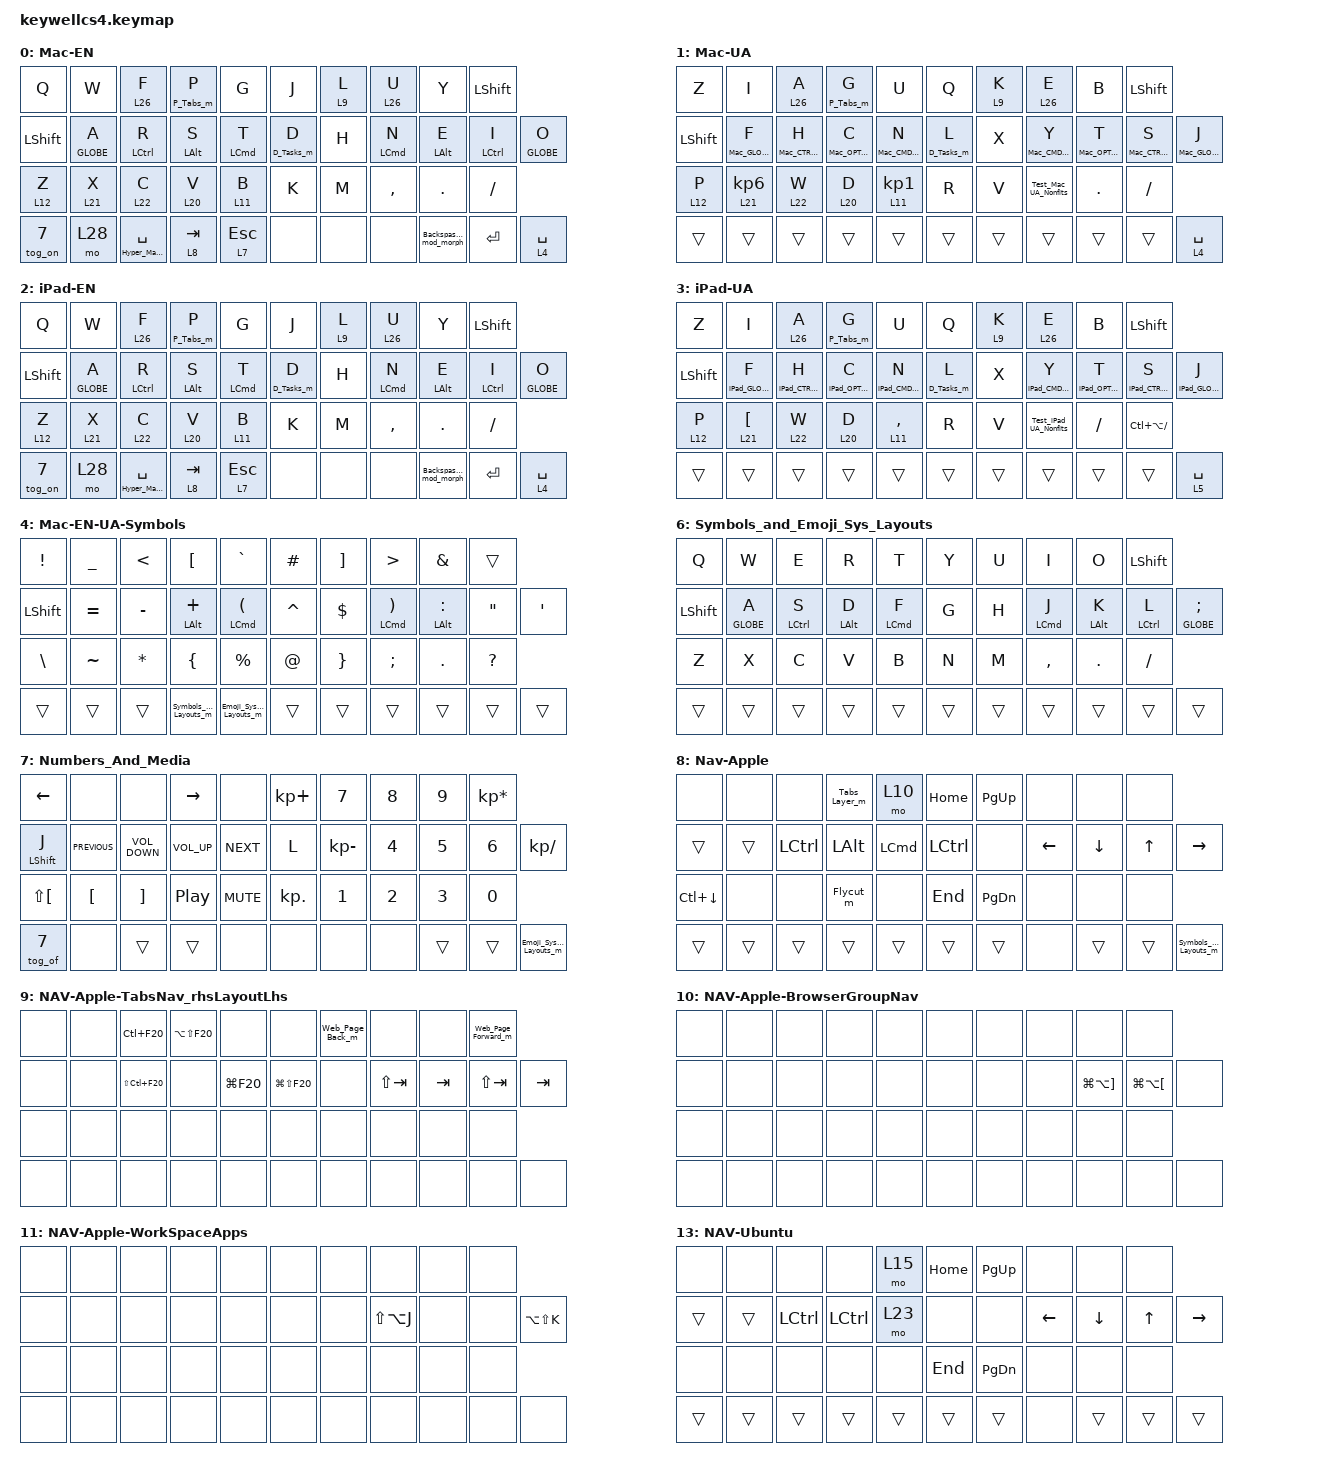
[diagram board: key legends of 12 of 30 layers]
/*
 * Copyright (c) 2020 The ZMK Contributors
 *
 * SPDX-License-Identifier: MIT
 */
// #include <dt-bindings/zmk/rgb.h>
// rob"s zmk unicode

#include <behaviors/unicode.dtsi>

/* MEH...
    Keycodes for other locales
    Gives nothing extra except key representation in visual editor
    https://github.com/nickcoutsos/keymap-editor/wiki/Keycodes-for-other-locales
*/
// #include "includes/keys_uk_enhanced.h"

#define DEFAULT 0
#define WARP  21
#define PRESISION  22

#include "includes/mouse.dtsi"
#include <zmk-unicode/keys-extra.h> // All Unicode glyphs except CJK
#include <behaviors.dtsi>
#include <dt-bindings/zmk/bt.h>
#include <dt-bindings/zmk/keys.h>
#include <dt-bindings/zmk/outputs.h>
#include <dt-bindings/zmk/pointing.h>

// rob"s zmk unicode

&uc {
    default-mode = <UC_MODE_MACOS>;
    minimum-length = <4>;
    macos-key = <LALT>;

    // linux-key = <LC(LS(U))>;
    // win-compose-key = <RALT>;
};

/ {
    behaviors {
        #include "includes/open_app_tap_dances.dtsi"

        Mac_CMD_nonEN_WA_LHRM: Mac_CMD_nonEN_WA_LHRM {
            compatible = "zmk,behavior-hold-tap";
            label = "MAC_CMD_NONEN_WA_LHRM";
            bindings = <&Mac_CMD_Shortcuts_NonEN_WA_m>, <&kp>;

            #binding-cells = <2>;
            flavor = "balanced";
            tapping-term-ms = <180>;
            quick-tap-ms = <175>;
            require-prior-idle-ms = <150>;
            hold-trigger-on-release;
            hold-trigger-key-positions = <5 6 7 8 15 16 17 18 25 26 27 28 36 37 38 39 40 41 30 31 32 33 34 35 9 19 29>;
        };

        Mac_CMD_nonEN_WA_RHRM: Mac_CMD_nonEN_WA_RHRM {
            compatible = "zmk,behavior-hold-tap";
            label = "MAC_CMD_NONEN_WA_RHRM";
            bindings = <&Mac_CMD_Shortcuts_NonEN_WA_m>, <&kp>;

            #binding-cells = <2>;
            flavor = "balanced";
            tapping-term-ms = <180>;
            quick-tap-ms = <175>;
            require-prior-idle-ms = <150>;
            hold-trigger-on-release;
            hold-trigger-key-positions = <0 1 2 3 4 10 11 12 13 14 21 22 23 24 31 32 33 34 35 36 37 38 39 40 41 30 25 15 20>;
        };

        Mac_OPT_nonEN_WA_LHRM: Mac_OPT_nonEN_WA_LHRM {
            compatible = "zmk,behavior-hold-tap";
            label = "MAC_OPT_NONEN_WA_LHRM";
            bindings = <&Mac_OPT_Shortcuts_NonEN_WA_m>, <&kp>;

            #binding-cells = <2>;
            flavor = "balanced";
            tapping-term-ms = <180>;
            quick-tap-ms = <175>;
            require-prior-idle-ms = <150>;
            hold-trigger-on-release;
            hold-trigger-key-positions = <5 6 7 8 15 16 17 18 25 26 27 28 36 37 38 39 40 41 30 31 32 33 34 35 9 19 29>;
        };

        Mac_OPT_nonEN_WA_RHRM: Mac_OPT_nonEN_WA_RHRM {
            compatible = "zmk,behavior-hold-tap";
            label = "MAC_OPT_NONEN_WA_RHRM";
            bindings = <&Mac_OPT_Shortcuts_NonEN_WA_m>, <&kp>;

            #binding-cells = <2>;
            flavor = "balanced";
            tapping-term-ms = <180>;
            quick-tap-ms = <175>;
            require-prior-idle-ms = <150>;
            hold-trigger-on-release;
            hold-trigger-key-positions = <0 1 2 3 4 10 11 12 13 14 21 22 23 24 31 32 33 34 35 36 37 38 39 40 41 30 25 15 20>;
        };

        Mac_CTRL_nonEN_WA_LHRM: Mac_CTRL_nonEN_WA_LHRM {
            compatible = "zmk,behavior-hold-tap";
            label = "MAC_CTRL_NONEN_WA_LHRM";
            #binding-cells = <2>;
            flavor = "balanced";
            tapping-term-ms = <180>;
            quick-tap-ms = <175>;
            require-prior-idle-ms = <150>;
            hold-trigger-on-release;
            hold-trigger-key-positions = <5 6 7 8 15 16 17 18 25 26 27 28 36 37 38 39 40 41 30 31 32 33 34 35 9 19 29>;
            bindings = <&Mac_CTRL_Shortcuts_NonEN_WA_m>, <&kp>;
        };

        Mac_CTRL_nonEN_WA_RHRM: Mac_CTRL_nonEN_WA_RHRM {
            compatible = "zmk,behavior-hold-tap";
            label = "MAC_CTRL_NONEN_WA_RHRM";
            #binding-cells = <2>;
            flavor = "balanced";
            tapping-term-ms = <180>;
            quick-tap-ms = <175>;
            require-prior-idle-ms = <150>;
            hold-trigger-on-release;
            bindings = <&Mac_CTRL_Shortcuts_NonEN_WA_m>, <&kp>;

            hold-trigger-key-positions = <0 1 2 3 4 10 11 12 13 14 20 21 22 23 24 30 31 32 33 34 35 36 37 38 39 40 41>;
        };

        Mac_GLOBE_nonEN_WA_LHRM: Mac_GLOBE_nonEN_WA_LHRM {
            compatible = "zmk,behavior-hold-tap";
            label = "MAC_GLOBE_NONEN_WA_LHRM";
            #binding-cells = <2>;
            flavor = "balanced";
            tapping-term-ms = <180>;
            quick-tap-ms = <175>;
            require-prior-idle-ms = <150>;
            hold-trigger-on-release;
            hold-trigger-key-positions = <5 6 7 8 15 16 17 18 25 26 27 28 36 37 38 39 40 41 30 31 32 33 34 35 9 19 29>;
            bindings = <&Mac_GLOBE_Shortcuts_NonEN_WA_m>, <&kp>;
        };

        Mac_GLOBE_nonEN_WA_RHRM: Mac_GLOBE_nonEN_WA_RHRM {
            compatible = "zmk,behavior-hold-tap";
            label = "MAC_GLOBE_NONEN_WA_RHRM";
            #binding-cells = <2>;
            flavor = "balanced";
            tapping-term-ms = <180>;
            quick-tap-ms = <175>;
            require-prior-idle-ms = <150>;
            hold-trigger-on-release;
            bindings = <&Mac_GLOBE_Shortcuts_NonEN_WA_m>, <&kp>;

            hold-trigger-key-positions = <0 1 2 3 4 10 11 12 13 14 20 21 22 23 24 30 31 32 33 34 35 36 37 38 39 40 41>;
        };

        iPad_CMD_Phonetic_UA_LHRM: iPad_CMD_Phonetic_UA_LHRM {
            compatible = "zmk,behavior-hold-tap";
            label = "IPAD_CMD_PHONETIC_UA_LHRM";
            bindings = <&iPad_CMD_Phonetic_UA_m>, <&kp>;

            #binding-cells = <2>;
            flavor = "balanced";
            tapping-term-ms = <180>;
            quick-tap-ms = <175>;
            require-prior-idle-ms = <150>;
            hold-trigger-on-release;
            hold-trigger-key-positions = <5 6 7 8 15 16 17 18 25 26 27 28 36 37 38 39 40 41 30 31 32 33 34 35 9 19 29>;
        };

        iPad_CMD_Phonetic_UA_RHRM: iPad_CMD_Phonetic_UA_RHRM {
            compatible = "zmk,behavior-hold-tap";
            label = "IPAD_CMD_PHONETIC_UA_RHRM";
            bindings = <&iPad_CMD_Phonetic_UA_m>, <&kp>;

            #binding-cells = <2>;
            flavor = "balanced";
            tapping-term-ms = <180>;
            quick-tap-ms = <175>;
            require-prior-idle-ms = <150>;
            hold-trigger-on-release;
            hold-trigger-key-positions = <0 1 2 3 4 10 11 12 13 14 21 22 23 24 31 32 33 34 35 36 37 38 39 40 41 30 25 15 20>;
        };

        iPad_OPT_Phonetic_UA_LHRM: iPad_OPT_Phonetic_UA_LHRM {
            compatible = "zmk,behavior-hold-tap";
            label = "IPAD_OPT_PHONETIC_UA_LHRM";
            bindings = <&iPad_OPT_Phonetic_UA_m>, <&kp>;

            #binding-cells = <2>;
            flavor = "balanced";
            tapping-term-ms = <180>;
            quick-tap-ms = <175>;
            require-prior-idle-ms = <150>;
            hold-trigger-on-release;
            hold-trigger-key-positions = <5 6 7 8 15 16 17 18 25 26 27 28 36 37 38 39 40 41 30 31 32 33 34 35 9 19 29>;
        };

        iPad_OPT_Phonetic_UA_RHRM: iPad_OPT_Phonetic_UA_RHRM {
            compatible = "zmk,behavior-hold-tap";
            label = "IPAD_OPT_PHONETIC_UA_RHRM";
            bindings = <&iPad_OPT_Phonetic_UA_m>, <&kp>;

            #binding-cells = <2>;
            flavor = "balanced";
            tapping-term-ms = <180>;
            quick-tap-ms = <175>;
            require-prior-idle-ms = <150>;
            hold-trigger-on-release;
            hold-trigger-key-positions = <0 1 2 3 4 10 11 12 13 14 21 22 23 24 31 32 33 34 35 36 37 38 39 40 41 30 25 15 20>;
        };

        iPad_CTRL_Phonetic_UA_LHRM: iPad_CTRL_Phonetic_UA_LHRM {
            compatible = "zmk,behavior-hold-tap";
            label = "IPAD_CTRL_PHONETIC_UA_LHRM";
            #binding-cells = <2>;
            flavor = "balanced";
            tapping-term-ms = <180>;
            quick-tap-ms = <175>;
            require-prior-idle-ms = <150>;
            hold-trigger-on-release;
            hold-trigger-key-positions = <5 6 7 8 15 16 17 18 25 26 27 28 36 37 38 39 40 41 30 31 32 33 34 35 9 19 29>;
            bindings = <&iPad_CTRL_Phonetic_UA_m>, <&kp>;
        };

        iPad_CTRL_Phonetic_UA_RHRM: iPad_CTRL_Phonetic_UA_RHRM {
            compatible = "zmk,behavior-hold-tap";
            label = "IPAD_CTRL_PHONETIC_UA_RHRM";
            #binding-cells = <2>;
            flavor = "balanced";
            tapping-term-ms = <180>;
            quick-tap-ms = <175>;
            require-prior-idle-ms = <150>;
            hold-trigger-on-release;
            bindings = <&iPad_CTRL_Phonetic_UA_m>, <&kp>;

            hold-trigger-key-positions = <0 1 2 3 4 10 11 12 13 14 20 21 22 23 24 30 31 32 33 34 35 36 37 38 39 40 41>;
        };

        iPad_GLOBE_Phonetic_UA_LHRM: iPad_GLOBE_Phonetic_UA_LHRM {
            compatible = "zmk,behavior-hold-tap";
            label = "IPAD_GLOBE_PHONETIC_UA_LHRM";
            #binding-cells = <2>;
            flavor = "balanced";
            tapping-term-ms = <180>;
            quick-tap-ms = <175>;
            require-prior-idle-ms = <150>;
            hold-trigger-on-release;
            hold-trigger-key-positions = <5 6 7 8 15 16 17 18 25 26 27 28 36 37 38 39 40 41 30 31 32 33 34 35 9 19 29>;
            bindings = <&iPad_GLOBE_Phonetic_UA_m>, <&kp>;
        };

        iPad_GLOBE_Phonetic_UA_RHRM: iPad_GLOBE_Phonetic_UA_RHRM {
            compatible = "zmk,behavior-hold-tap";
            label = "IPAD_GLOBE_PHONETIC_UA_RHRM";
            #binding-cells = <2>;
            flavor = "balanced";
            tapping-term-ms = <180>;
            quick-tap-ms = <175>;
            require-prior-idle-ms = <150>;
            hold-trigger-on-release;
            bindings = <&iPad_GLOBE_Phonetic_UA_m>, <&kp>;

            hold-trigger-key-positions = <0 1 2 3 4 10 11 12 13 14 20 21 22 23 24 30 31 32 33 34 35 36 37 38 39 40 41>;
        };

        hml: hml {
            compatible = "zmk,behavior-hold-tap";
            label = "HML";
            bindings = <&kp>, <&kp>;

            #binding-cells = <2>;
            flavor = "balanced";
            tapping-term-ms = <280>;
            quick-tap-ms = <175>;
            require-prior-idle-ms = <150>;
            hold-trigger-key-positions = <5 6 7 8 9 15 16 17 18 19 25 26 27 28 29 30 31 32 33 34 35 36 39 37 38 37 38 40 41 20>;
            hold-trigger-on-release;
        };

        hmr: hmr {
            compatible = "zmk,behavior-hold-tap";
            label = "HMR";
            bindings = <&kp>, <&kp>;

            #binding-cells = <2>;
            flavor = "balanced";
            tapping-term-ms = <280>;
            quick-tap-ms = <175>;
            require-prior-idle-ms = <150>;
            hold-trigger-on-release;
            hold-trigger-key-positions = <0 1 2 3 4 10 11 12 13 14 21 22 23 24 31 32 33 34 35 36 37 38 39 40 41 25 15>;
        };

        Layer_Tap_Timeless_Left: Layer_Tap_Timeless_Left {
            compatible = "zmk,behavior-hold-tap";
            label = "LAYER_TAP_TIMELESS_LEFT";
            bindings = <&mo>, <&kp>;

            #binding-cells = <2>;
            flavor = "balanced";
            tapping-term-ms = <280>;
            quick-tap-ms = <175>;
            require-prior-idle-ms = <150>;
            hold-trigger-on-release;
            hold-trigger-key-positions = <5 6 7 8 9 16 17 18 19 20 26 27 28 29 30 36 37 38 39 40 41 14 11 12 13>;
        };

        Backspase_MacLike_mod_morph: maclike_backspace_delete {
            compatible = "zmk,behavior-mod-morph";
            #binding-cells = <0>;
            bindings = <&kp BACKSPACE>, <&kp DELETE>;

            mods = <(MOD_LSFT)>;   // when LEFT_SHIFT is held
            keep-mods = <0>;       // don't send Shift with Delete
        };

        kt_on: key_toggle_on_only {
            compatible = "zmk,behavior-key-toggle";
            #binding-cells = <1>;
            toggle-mode = "on";   // only presses, never releases
        };

        kt_off: key_toggle_off_only {
            compatible = "zmk,behavior-key-toggle";
            #binding-cells = <1>;
            toggle-mode = "off";  // only releases, never presses
        };

        tog_on: toggle_layer_on_only {
            compatible = "zmk,behavior-toggle-layer";
            #binding-cells = <1>;
            display-name = "Toggle Layer On";
            toggle-mode = "on";
        };

        tog_of: toggle_layer_of_only {
            compatible = "zmk,behavior-toggle-layer";
            #binding-cells = <1>;
            display-name = "Toggle Layer On";
            toggle-mode = "off";
        };

        HyperMac_HT_Timeless: holdTapMacroKp {
            compatible = "zmk,behavior-hold-tap";
            label = "Hyper";
            bindings = <&Hyper_Mac_m>, <&kp>;

            #binding-cells = <2>;
            tapping-term-ms = <173>;
            hold-trigger-key-positions = <
0 1 2 3 4 5 6 7 8 9 10 11 12 13 14 15 16 17 18 19 20 21 22 23 24 25 26 27 28 29 30 31 32 33 34 35 36 37 38
             39 40 4
            >;
        };

        D_Tasks_Timeless_left: D_Tasks_Timeless_left {
            compatible = "zmk,behavior-hold-tap";
            label = "D_TASKS_TIMELESS_LEFT";
            bindings = <&D_Tasks_m>, <&kp>;

            #binding-cells = <2>;
            flavor = "balanced";
            tapping-term-ms = <280>;
            quick-tap-ms = <175>;
            require-prior-idle-ms = <150>;
            hold-trigger-key-positions = <5 6 7 8 9 16 17 18 19 26 27 28 29 30 31 32 33 34 35 36 39 37 38 37 38 40 41 20>;
            hold-trigger-on-release;
        };

        UbuntuAppSwWA_Timeless: UbuntuAppSwWA_Timeless {
            compatible = "zmk,behavior-hold-tap";
            label = "UBUNTUAPPSWWA_TIMELESS";
            bindings = <&Ubuntu_App_SW_WA_m>, <&kp>;

            #binding-cells = <2>;
            flavor = "balanced";
            tapping-term-ms = <280>;
            quick-tap-ms = <175>;
            require-prior-idle-ms = <150>;
            hold-trigger-key-positions = <5 6 7 8 9 16 17 18 19 26 27 28 29 30 31 32 33 34 35 36 39 37 38 37 38 40 41 20>;
            hold-trigger-on-release;
        };

        P_Tabs_Timeless_left: P_Tabs_Timeless_left {
            compatible = "zmk,behavior-hold-tap";
            label = "P_TABS_TIMELESS_LEFT";
            bindings = <&P_Tabs_m>, <&kp>;

            #binding-cells = <2>;
            flavor = "balanced";
            tapping-term-ms = <280>;
            quick-tap-ms = <175>;
            require-prior-idle-ms = <150>;
            hold-trigger-key-positions = <5 6 7 8 9 16 17 18 19 26 27 28 29 30 31 32 33 34 35 36 39 37 38 37 38 40 41 20>;
            hold-trigger-on-release;
        };

        Layer_Tap_Timeless_Right: Layer_Tap_Timeless_Right {
            compatible = "zmk,behavior-hold-tap";
            label = "LAYER_TAP_TIMELESS_RIGHT";
            bindings = <&mo>, <&kp>;

            #binding-cells = <2>;
            flavor = "balanced";
            tapping-term-ms = <280>;
            quick-tap-ms = <175>;
            require-prior-idle-ms = <150>;
            hold-trigger-on-release;
            hold-trigger-key-positions = <0 1 2 3 4 10 11 12 13 14 15 21 22 23 24 25 31 32 34 35 33>;
        };

        UbuntuWindowsSwWA: UbuntuWindowsSwWA {
            compatible = "zmk,behavior-hold-tap";
            label = "UBUNTUWINDOWSSWWA";
            bindings = <&Ubuntu_Windows_SW_WA_m>, <&kp>;

            #binding-cells = <2>;
            flavor = "balanced";
            tapping-term-ms = <280>;
            quick-tap-ms = <175>;
            require-prior-idle-ms = <150>;
            hold-trigger-key-positions = <5 6 7 8 9 16 17 18 19 26 27 28 29 30 31 32 33 34 35 36 39 37 38 37 38 40 41 20>;
            hold-trigger-on-release;
        };

        Thumb_HT_VeryShort: Thumb_HT_VeryShort {
            compatible = "zmk,behavior-hold-tap";
            label = "THUMB_HT_VERYSHORT";
            bindings = <&mo>, <&kp>;

            #binding-cells = <2>;
            tapping-term-ms = <120>;
            hold-trigger-key-positions = <
0 1 2 3 4 5 6 7 8 9 10 11 12 13 14 15 16 17 18 19 20 21 22 23 24 25 26 27 28 29 30 31 32 33 34 35 36 37 38
             39 40 4
            >;

            quick-tap-ms = <175>;
            flavor = "balanced";
            hold-trigger-on-release;
        };

        Sticky_1500ms: Sticky_1500ms {
            compatible = "zmk,behavior-sticky-key";
            label = "STICKY_1500MS";
            bindings = <&kp>;
            #binding-cells = <1>;
            release-after-ms = <1500>;
        };

        Thumb_HT_Normal: Thumb_HT_Normal {
            compatible = "zmk,behavior-hold-tap";
            label = "THUMB_HT_NORMAL";
            bindings = <&mo>, <&kp>;

            #binding-cells = <2>;
            tapping-term-ms = <178>;
            hold-trigger-key-positions = <
0 1 2 3 4 5 6 7 8 9 10 11 12 13 14 15 16 17 18 19 20 21 22 23 24 25 26 27 28 29 30 31 32 33 34 35 36 37 38
             39 40 4
            >;

            quick-tap-ms = <175>;
            flavor = "balanced";
            hold-trigger-on-release;
        };

        leaderKey_1: leaderKey_1 {
            compatible = "zmk,behavior-leader-key";
            #binding-cells = <0>;

            KeyCluShowShortcutsFix {
                sequence = <S H O>;
                bindings = <&KeyClu_Show_Shortcuts_m>;
            };
        };

        Test_Mac_UA_Nonfits: Test_Mac_UA_Nonfits {
            compatible = "zmk,behavior-tap-dance";
            label = "TEST_MAC_UA_NONFITS";
            #binding-cells = <0>;
            bindings = <&kp COMMA>, <&sl 18>;

            tapping-term-ms = <350>;
        };

        Test_iPad_UA_Nonfits: Test_iPad_UA_Nonfits {
            compatible = "zmk,behavior-tap-dance";
            label = "TEST_IPAD_UA_NONFITS";
            #binding-cells = <0>;
            bindings = <&kp LS(SLASH)>, <&sl 29>;

            tapping-term-ms = <350>;
        };

        ht_sys_sub_layouts: ht_sys_sub_layouts {
            compatible = "zmk,behavior-hold-tap";
            label = "HT_SYS_SUB_LAYOUTS";
            bindings = <&kp>, <&kp>;

            #binding-cells = <2>;
            tapping-term-ms = <128>;
            hold-trigger-key-positions = <0 1 2 3 4 10 11 12 14 15 21 22 23 25 24 5 6 7 8 9 30 19 20 29 28 18 17 16 26 27 13>;
            quick-tap-ms = <175>;
        };
    };

    combos {
        compatible = "zmk,combos";

        #include "includes/cyrillic_letters_combos.dtsi"

        combo_CmdTAbAppSW {
            bindings = <&CmdTAb_App_SW_m>;
            key-positions = <34 25>;
            layers = <0 1 2 3>;
            timeout-ms = <150>;
        };

        Mac_OneHanded_Sticky_Command {
            bindings = <&Sticky_1500ms LEFT_COMMAND>;
            key-positions = <24 23>;
            layers = <0 1 8 2 3>;
        };

        Ubuntu_OneHanded_Sticky_Control {
            bindings = <&Sticky_1500ms LEFT_CONTROL>;
            key-positions = <24 23>;
            layers = <27>;
        };

        Mac-Switch-To-UA-combo {
            /*
                Should only possible when Ukrainian language is in use (i.e. combo active on Ua shortcuts fix layer is on).
                On this depends syncronized swithcing of OS language & ZMK layouts for iPad
            */

            bindings = <&Mac_Switch_To_UA_m>;
            key-positions = <28 29>;
            layers = <0>;
            timeout-ms = <170>; // must be less than hold-tap of a key that used both in hold-tap and combo. Or there will be race conditions and WATs.
        };

        Mac-Switch-To-EN-combo {
            /*
                Should only possible when Englist language is in use (i.e. combo active on Colemac layer only).
                On this depends syncronized swithcing of OS language & ZMK layouts for iPad
            */

            bindings = <&Mac_Switch_To_EN_m>;
            key-positions = <27 28>;
            layers = <1>;
            timeout-ms = <170>; // must be less than hold-tap of a key that used both in hold-tap and combo. Or there will be race conditions and WATs.
        };

        Mac_Suppress-EN-for-EN {
            // when En Seleced, combo to switch to EN disabled. When you blindly hit keys of this combo, to ensure you
            // on EN, being on EN already, itnsead of combo you get letters typed. This is annoying to delete then.
            // So suppress these combination of letters, by having them in a same combo as EN but producing nothing.

            bindings = <&none>;
            key-positions = <28 27>;
            timeout-ms = <170>;
            layers = <0>;
        };

        Mac-UA-Accent-Dead-Key {
            /*
                Second role is Supressor for Ua/Uk. Read in other's conterpart combos. Either not delete, or implement
                then this role elswere.
            */

            bindings = <&kp LA(KP_NUMBER_0)>;
            key-positions = <28 29>;
            timeout-ms = <170>;
            layers = <1>;
        };

        iPad-Switch-To-EN-combo {
            // Read in Mac counterpat combo

            bindings = <&iPad_EN_m>;
            key-positions = <27 28>;
            timeout-ms = <190>; // must be less than hold-tap of a key that used both in hold-tap and combo. Or there will be race conditions and WATs
            layers = <3>;
        };

        iPad-Switch-To-UA-combo {
            // Read in Mac counterpat combo

            bindings = <&iPad_UA_m>;
            key-positions = <28 29>;
            timeout-ms = <190>; // must be less than hold-tap of a key that used both in hold-tap and combo. Or there will be race conditions and WATs
            layers = <2>;
        };

        iPad-Suppress-EN-for-EN-combo {
            // read mac counterpart combos or search "supress"

            bindings = <&none>;
            key-positions = <28 27>;
            timeout-ms = <190>;
            layers = <2>;
        };

        iPad-Suppress-UA-for-UA-combo {
            // read mac counterpart combos or search "supress"

            bindings = <&none>;
            key-positions = <28 29>;
            timeout-ms = <190>;
            layers = <3>;
        };

        Delete_Word_Apple {
            bindings = <&kp LA(BACKSPACE)>;
            key-positions = <17 18>;
            layers = <0 1 2 3>;
            require-prior-idle-ms = <320>;
        };

        Delete_Word_Ubuntu {
            bindings = <&kp LC(BACKSPACE)>;
            key-positions = <17 18>;
            require-prior-idle-ms = <320>;
            layers = <27>;
        };

        AppWindowsSwNextP1 {
            bindings = <&kp LG(GRAVE)>;
            key-positions = <21 14>;
            timeout-ms = <150>;
            layers = <0 1>;
        };

        AppWindowsSwNextP2 {
            bindings = <&kp LG(GRAVE)>;
            key-positions = <21 13>;
            timeout-ms = <150>;
            layers = <0 1>;
        };

        AppWindowsSwPrevP1 {
            bindings = <&kp LG(LS(GRAVE))>;
            key-positions = <21 11>;
            timeout-ms = <150>;
            layers = <0 1>;
        };

        AppWindowsSwPrevP2 {
            bindings = <&kp LG(LS(GRAVE))>;
            key-positions = <21 12>;
            timeout-ms = <150>;
            layers = <0 1>;
        };

        MediaLayerStickLikeWP {
            bindings = <&to 7>;
            key-positions = <1 3>;
            timeout-ms = <150>;
            layers = <7>;
        };

        AND {
            bindings = <&AND_m>;
            key-positions = <7 8>;
            layers = <4 5>;
        };

        OR {
            bindings = <&OR_m>;
            key-positions = <21 22>;
            layers = <4 5>;
            timeout-ms = <100>;
        };

        PutWordInQuotes {
            bindings = <&Put_Word_In_Quotes_m>;
            key-positions = <19 18>;
            layers = <4 5>;
        };

        KeyCluShowShortcutsLeftCombo {
            bindings = <&leaderKey_1>;
            key-positions = <20 11>;
            layers = <0 1>;
        };

        //-------------------------------------------    For OS in UA-Colemak    -------------------------------------------
        /*       UA_COLEMAK_SC {
            bindings = <&kp KP_NUMBER_1>;
            key-positions = <1 2>;
            timeout-ms = <190>;
        };

        UA_COLEMAK_JU {
            bindings = <&kp KP_NUMBER_4>;
            key-positions = <7 8>;
            timeout-ms = <190>;
        };

        UA_COLEMAK_JI {
            bindings = <&kp KP_NUMBER_5>;
            key-positions = <19 20>;
            timeout-ms = <190>;
        };

        UA_COLEMAK_G_tverde {
            bindings = <&kp KP_NUMBER_2>;
            key-positions = <3 2>;
            timeout-ms = <190>;
        };

        UA_COLEMAK_ZJ {
            bindings = <&kp KP_NUMBER_0>;
            key-positions = <6 7>;
            timeout-ms = <190>;
        };

        UA_COLEMAK_Miaki_ZNAK {
            bindings = <&kp KP_NUMBER_6>;
            key-positions = <18 27>;
            timeout-ms = <190>;
        };

        UA_COLEMAK_JE {
            bindings = <&kp KP_NUMBER_3>;
            key-positions = <18 19>;
            timeout-ms = <190>;
        };

        //---------------------------------------------    For OS in QWERTY    ---------------------------------------------

        UA_QWERTY_SC {
            bindings = <&kp O>;
            key-positions = <1 2>;
            timeout-ms = <190>;
            layers = <4>;
        };

        UA_QWERTY_JU {
            bindings = <&kp PERIOD>;
            key-positions = <7 8>;
            timeout-ms = <190>;
            layers = <4>;
        };

        UA_QWERTY_JI {
            bindings = <&kp RIGHT_BRACKET>;
            key-positions = <19 20>;
            timeout-ms = <190>;
            layers = <4>;
        };

        UA_QWERTY_G_tverde {
            bindings = <&kp GRAVE>;
            key-positions = <3 2>;
            timeout-ms = <190>;
            layers = <4>;
        };

        UA_QWERTY_ZJ {
            bindings = <&kp SEMI>;
            key-positions = <6 7>;
            timeout-ms = <190>;
            layers = <4>;
        };

        UA_QWERTY_Miaki_ZNAK {
            bindings = <&kp M>;
            key-positions = <18 27>;
            timeout-ms = <190>;
            layers = <4>;
        };

        UA_QWERTY_JE {
            bindings = <&kp APOSTROPHE>;
            key-positions = <18 19>;
            timeout-ms = <190>;
            layers = <4>;
        };*/
    };

    macros {
        #include "includes/open_app_shortcuts_macros.dtsi"

        Mac_CMD_Shortcuts_NonEN_WA_m: Mac_CMD_Shortcuts_NonEN_WA_m {
            /*
                f21/F22 - if you want have regular keyboard change layouts to a particular with Bigram/Hyper Layer -
                make it separete shortcut (like ol' LE / LU) ^16499de1
            */

            compatible = "zmk,behavior-macro";
            label = "MAC_CMD_SHORTCUTS_NONEN_WA_M";
            tap-ms = <0>;
            wait-ms = <0>;
            #binding-cells = <0>;
            bindings =
                <&kp F21 &tog_of 1 &kt_on LCMD>,
                <&macro_pause_for_release>,
                <&kt_off LCMD &kp LS(F21) &tog_on 1>;
        };

        Mac_OPT_Shortcuts_NonEN_WA_m: Mac_OPT_Shortcuts_NonEN_WA_m {
            compatible = "zmk,behavior-macro";
            label = "MAC_OPT_SHORTCUTS_NONEN_WA_M";
            tap-ms = <0>;
            wait-ms = <0>;
            #binding-cells = <0>;
            bindings =
                <&kp F21 &tog_of 1 &kt_on LEFT_ALT>,
                <&macro_pause_for_release>,
                <&kt_off LEFT_ALT &kp LS(F21) &tog_on 1>;
        };

        Mac_CTRL_Shortcuts_NonEN_WA_m: Mac_CTRL_Shortcuts_NonEN_WA_m {
            // read ^16499de1

            compatible = "zmk,behavior-macro";
            label = "MAC_CTRL_SHORTCUTS_NONEN_WA_M";
            tap-ms = <0>;
            wait-ms = <0>;
            #binding-cells = <0>;
            bindings =
                <&kp F21 &tog_of 1 &kt_on LEFT_CONTROL>,
                <&macro_pause_for_release>,
                <&kt_off LEFT_CONTROL &kp LS(F21) &tog_on 1>;
        };

        Mac_GLOBE_Shortcuts_NonEN_WA_m: Mac_GLOBE_Shortcuts_NonEN_WA_m {
            // read ^16499de1

            compatible = "zmk,behavior-macro";
            tap-ms = <0>;
            wait-ms = <0>;
            #binding-cells = <0>;
            bindings =
                <&kp F21 &tog_of 1 &kt_on GLOBE>,
                <&macro_pause_for_release>,
                <&kt_off GLOBE &kp LS(F21) &tog_on 1>;

            label = "MAC_GLOBE_SHORTCUTS_NONEN_WA_M";
        };

        iPad_CMD_Phonetic_UA_m: iPad_CMD_Phonetic_UA_m {
            compatible = "zmk,behavior-macro";
            label = "IPAD_CMD_PHONETIC_UA_M";
            tap-ms = <0>;
            wait-ms = <0>;
            #binding-cells = <0>;
            bindings =
                <&tog_of 1 &kt_on LCMD>,
                <&macro_pause_for_release>,
                <&kt_off LCMD &tog_on 1>;
        };

        iPad_OPT_Phonetic_UA_m: iPad_OPT_Phonetic_UA_m {
            compatible = "zmk,behavior-macro";
            label = "IPAD_OPT_PHONETIC_UA_M";
            tap-ms = <0>;
            wait-ms = <0>;
            #binding-cells = <0>;
            bindings =
                <&tog_of 1 &kt_on LEFT_ALT>,
                <&macro_pause_for_release>,
                <&kt_off LEFT_ALT &tog_on 1>;
        };

        iPad_CTRL_Phonetic_UA_m: iPad_CTRL_Phonetic_UA_m {
            compatible = "zmk,behavior-macro";
            label = "IPAD_CTRL_PHONETIC_UA_M";
            tap-ms = <0>;
            wait-ms = <0>;
            #binding-cells = <0>;
            bindings =
                <&tog_of 1 &kt_on LEFT_CONTROL>,
                <&macro_pause_for_release>,
                <&kt_off LEFT_CONTROL &tog_on 1>;
        };

        iPad_GLOBE_Phonetic_UA_m: iPad_GLOBE_Phonetic_UA_m {
            compatible = "zmk,behavior-macro";
            tap-ms = <0>;
            wait-ms = <0>;
            #binding-cells = <0>;
            bindings =
                <&tog_of 1 &kt_on GLOBE>,
                <&macro_pause_for_release>,
                <&kt_off GLOBE &tog_on 1>;

            label = "IPAD_GLOBE_PHONETIC_UA_M";
        };

        CmdTAb_App_SW_m: CmdTAb_App_SW_m {
            /*
                - ! Don't asign to holds of hold-taps as in standard user press CMD+TAB faster and it will not trigger
                  in time
                - wait and tap time of at least 30ms is recommended to avoid having HID notifications grouped at the BLE
                  protocol level and then processed out of order
            */

            compatible = "zmk,behavior-macro";
            #binding-cells = <0>;
            bindings =
                <&macro_press>,
                <&kp LCMD &mo 8 &kp TAB>,
                <&macro_wait_time 100>,
                <&macro_release>,
                <&kp TAB>,
                <&macro_wait_time 1>,
                <&macro_pause_for_release>,
                <&macro_release>,
                <&mo 8 &kp LCMD>;

            label = "CMDTAB_APP_SW_M";
            tap-ms = <1>;  // not used as no taps
            wait-ms = <1>;  // make initial cmd press down asap
        };

        Mac_BT_m: Mac_BT_m {
            compatible = "zmk,behavior-macro";
            tap-ms = <0>;
            wait-ms = <0>;
            #binding-cells = <0>;
            bindings = <&bt BT_SEL 0 &tog_of 1 &tog_of 2 &tog_of 3 &tog_of 27 &bt BT_DISC 1 &bt BT_DISC 2 &bt BT_DISC 3 &bt BT_DISC 4>;
            label = "MAC_BT_M";
        };

        iPad_BT_m: iPad_BT_m {
            compatible = "zmk,behavior-macro";
            tap-ms = <0>;
            wait-ms = <0>;
            #binding-cells = <0>;
            bindings = <&bt BT_SEL 1 &tog_of 1 &tog_on 2 &tog_of 3 &tog_of 27 &bt BT_DISC 0 &bt BT_DISC 2 &bt BT_DISC 3 &bt BT_DISC 4>;
            label = "IPAD_BT_M";
        };

        Ubuntu_BT_m: Ubuntu_BT_m {
            compatible = "zmk,behavior-macro";
            tap-ms = <0>;
            wait-ms = <0>;
            #binding-cells = <0>;
            bindings = <&bt BT_SEL 2 &tog_of 1 &tog_of 2 &tog_of 3 &tog_on 27 &bt BT_DISC 0 &bt BT_DISC 1 &bt BT_DISC 3 &bt BT_DISC 4>;
            label = "UBUNTU_BT_M";
        };

        Hyper_Mac_m: Hyper_Mac_m {
            // Supports hyper by standing it above hrm layer. ie swithes to plain letters + hyperKey

            compatible = "zmk,behavior-macro";
            label = "HYPER_MAC_M";
            #binding-cells = <0>;
            tap-ms = <0>;
            wait-ms = <0>;
            bindings =
                <&macro_press>,
                <&mo 24>,
                <&macro_press>,
                <&kp F16>,
                <&macro_pause_for_release>,
                <&macro_release>,
                <&mo 24>,
                <&macro_release>,
                <&kp F16>;
        };

        Mac_Switch_To_UA_m: Mac_Switch_To_UA_m {
            /*
                Macro is mandatory. As keyboard must switch zmk layout too (in addition to sending language changing key
                sequence to karabener which is not possible wo macro)

                For rdp/vnc/remote Karabiner doesn't work. To switch system layouts remotely bypass karabiner.
                For example by using Apple Script added as a service with shortcut.
    		*/

            compatible = "zmk,behavior-macro";
            tap-ms = <0>;
            wait-ms = <0>;
            #binding-cells = <0>;
            bindings = <&kp LS(F21) &tog_on 1>;
            label = "MAC_SWITCH_TO_UA_M";
        };

        Mac_Switch_To_EN_m: Mac_Switch_To_EN_m {
            // read ^16499de1

            compatible = "zmk,behavior-macro";
            tap-ms = <0>;
            wait-ms = <0>;
            #binding-cells = <0>;
            bindings = <&kp F21 &tog_of 1>;
            label = "MAC_SWITCH_TO_EN_M";
        };

        iPad_UA_m: iPad_UA_m {
            compatible = "zmk,behavior-macro";
            tap-ms = <0>;
            wait-ms = <0>;
            #binding-cells = <0>;
            bindings = <&kp CAPSLOCK &tog_on 3>;
            label = "IPAD_UA_M";
        };

        iPad_EN_m: iPad_EN_m {
            tap-ms = <0>;
            wait-ms = <0>;
            compatible = "zmk,behavior-macro";
            #binding-cells = <0>;
            bindings = <&kp CAPSLOCK &tog_of 3>;
            label = "IPAD_EN_M";
        };

        Ubuntu_Windows_SW_WA_m: Ubuntu_Windows_SW_WA_m {
            compatible = "zmk,behavior-macro";
            tap-ms = <0>;
            wait-ms = <0>;
            #binding-cells = <0>;
            bindings =
                <&kt_on RIGHT_ALT &tog_on 16>,
                <&macro_pause_for_release>,
                <&kt_off RIGHT_ALT &tog_of 16>;

            label = "UBUNTU_WINDOWS_SW_WA_M";
        };

        Ubuntu_App_SW_WA_m: Ubuntu_App_SW_WA_m {
            compatible = "zmk,behavior-macro";
            #binding-cells = <0>;
            tap-ms = <0>;
            wait-ms = <0>;
            bindings =
                <&kt_on RIGHT_ALT &tog_on 17>,
                <&macro_pause_for_release>,
                <&kt_off RIGHT_ALT &tog_of 17>;

            label = "UBUNTU_APP_SW_WA_M";
        };

        D_Tasks_m: D_Tasks_m {
            compatible = "zmk,behavior-macro";
            label = "D_TASKS_M";
            #binding-cells = <0>;
            tap-ms = <0>;
            wait-ms = <0>;
            bindings =
                <&macro_press>,
                <&mo 7>,
                <&macro_press>,
                <&kp LEFT_CONTROL>,
                <&macro_pause_for_release>,
                <&macro_release>,
                <&mo 7>,
                <&macro_release>,
                <&kp LEFT_CONTROL>;
        };

        P_Tabs_m: P_Tabs_m {
            compatible = "zmk,behavior-macro";
            label = "P_TABS_M";
            #binding-cells = <0>;
            tap-ms = <0>;
            wait-ms = <0>;
            bindings =
                <&macro_press>,
                <&mo 7>,
                <&macro_press>,
                <&kp LEFT_COMMAND>,
                <&macro_pause_for_release>,
                <&macro_release>,
                <&mo 7>,
                <&macro_release>,
                <&kp LEFT_COMMAND>;
        };

        Flycut_m: Flycut_m {
            compatible = "zmk,behavior-macro";
            tap-ms = <0>;
            wait-ms = <0>;
            #binding-cells = <0>;
            bindings =
                <&kt_on LEFT_ALT &kt LSHFT &kp V &tog_on 8>,
                <&macro_pause_for_release>,
                <&kt_off LEFT_ALT &kt_off LSHFT &tog_of 8>;

            label = "FLYCUT_M";
        };

        Tabs_Layer_m: Tabs_Layer_m {
            compatible = "zmk,behavior-macro";
            tap-ms = <0>;
            wait-ms = <0>;
            #binding-cells = <0>;
            bindings =
                <&kt_on LEFT_CONTROL &tog_on 9>,
                <&macro_pause_for_release>,
                <&kt_off LEFT_CONTROL &tog_of 9>;

            label = "TABS_LAYER_M";
        };

        Web_Page_Back_m: Web_Page_Back_m {
            compatible = "zmk,behavior-macro";
            tap-ms = <0>;
            wait-ms = <0>;
            #binding-cells = <0>;
            bindings = <&kt_off LEFT_CONTROL &kp LG(LEFT_BRACKET)>;
            label = "WEB_PAGE_BACK_M";
        };

        Web_Page_Forward_m: Web_Page_Forward_m {
            compatible = "zmk,behavior-macro";
            tap-ms = <0>;
            wait-ms = <0>;
            #binding-cells = <0>;
            bindings = <&kt_off LEFT_CONTROL &kp LG(RIGHT_BRACKET)>;
            label = "WEB_PAGE_FORWARD_M";
        };

        Put_Word_In_Quotes_m: Put_Word_In_Quotes_m {
            compatible = "zmk,behavior-macro";
            #binding-cells = <0>;
            bindings = <&kp LA(LEFT_ARROW) &kp DOUBLE_QUOTES &kp LA(RIGHT) &kp DOUBLE_QUOTES &kp SPACE>;
            label = "PUT_WORD_IN_QUOTES_M";
            wait-ms = <0>;
            tap-ms = <0>;
        };

        AND_m: AND_m {
            compatible = "zmk,behavior-macro";
            #binding-cells = <0>;
            bindings = <&kp SPACE &kp LS(A) &kp LS(N) &kp LS(D) &kp SPACE>;
            label = "AND_M";
            wait-ms = <0>;
            tap-ms = <0>;
        };

        OR_m: OR_m {
            compatible = "zmk,behavior-macro";
            #binding-cells = <0>;
            bindings = <&kp SPACE &kp LS(O) &kp LS(R) &kp SPACE>;
            label = "OR_M";
            wait-ms = <0>;
            tap-ms = <0>;
        };

        KeyClu_Show_Shortcuts_m: KeyClu_Show_Shortcuts_m {
            compatible = "zmk,behavior-macro";
            tap-ms = <0>;
            wait-ms = <0>;
            #binding-cells = <0>;
            bindings =
                <&macro_wait_time 300>,
                <&kp RIGHT_SHIFT &kp RIGHT_SHIFT &kt_on RIGHT_SHIFT>,
                <&macro_wait_time 1000>,
                <&kt_off RIGHT_SHIFT>;

            label = "KEYCLU_SHOW_SHORTCUTS_M";
        };

        Symbols_System_Layouts_m: Symbols_System_Layouts_m {
            compatible = "zmk,behavior-macro";
            label = "SYMBOLS_SYSTEM_LAYOUTS_M";
            tap-ms = <0>;
            wait-ms = <0>;
            #binding-cells = <0>;
            bindings =
                <&macro_press>,
                <&kp F22 &mo 6>,
                <&macro_pause_for_release>,
                <&macro_release>,
                <&kp F22 &mo 6>;
        };

        Emoji_System_Layouts_m: Emoji_System_Layouts_m {
            compatible = "zmk,behavior-macro";
            label = "EMOJI_SYSTEM_LAYOUTS_M";
            tap-ms = <0>;
            wait-ms = <0>;
            #binding-cells = <0>;
            bindings =
                <&macro_press>,
                <&kp F23 &mo 6>,
                <&macro_pause_for_release>,
                <&macro_release>,
                <&kp F23 &mo 6>;
        };

        mo_Fx_w_unpress_its_Hypr_key_m: mo_Fx_w_unpress_its_Hypr_key_m {
            compatible = "zmk,behavior-macro";
            label = "MO_FX_W_UNPRESS_ITS_HYPR_KEY_M";
            #binding-cells = <0>;
            tap-ms = <0>;
            wait-ms = <0>;
            bindings =
                <&kt_off F16>,
                <&macro_press>,
                <&mo 25>,
                <&macro_pause_for_release>,
                <&macro_release>,
                <&mo 25>;
        };

        iPhone_BT_m: iPhone_BT_m {
            compatible = "zmk,behavior-macro";
            tap-ms = <0>;
            wait-ms = <0>;
            #binding-cells = <0>;
            bindings = <&bt BT_SEL 3 &tog_of 1 &tog_of 27 &bt BT_DISC 0 &bt BT_DISC 1 &bt BT_DISC 2 &bt BT_DISC 4 &tog_on 2 &tog_of 3>;
            label = "IPHONE_BT_M";
        };
    };

    keymap {
        compatible = "zmk,keymap";

        Mac-EN {
            /*
                Keys physically like EN Colemak, but produce correct letters when system is in QWERTY (EN).
                This allows to type on devices where Colemak is not supported.
                Use Cases:
                    - iPad
                    - other people's machines
                    - remote Mac / Machines where you don't bother yourself or not allowed to set Colemak
            */

            bindings = <
&kp Q                          &kp W         &Layer_Tap_Timeless_Left 26 F  &P_Tabs_Timeless_left 0 P      &kp G                          &kp J                       &Layer_Tap_Timeless_Right 9 L  &Layer_Tap_Timeless_Right 26 U  &kp Y        &kp LEFT_SHIFT
&kp LEFT_SHIFT                 &hml GLOBE A  &hml LEFT_CONTROL R            &hml LALT S                    &hml LCMD T                    &D_Tasks_Timeless_left 0 D  &kp H                          &hmr LCMD N                     &hmr LALT E  &hmr LEFT_CONTROL I           &hmr GLOBE O
&Layer_Tap_Timeless_Left 12 Z  &lt 21 X      &lt 22 C                       &lt 20 V                       &Layer_Tap_Timeless_Left 11 B  &kp K                       &kp M                          &kp COMMA                       &kp DOT      &kp FSLH
                               &tog_on 7     &mo 28                         &HyperMac_HT_Timeless 0 SPACE  &Thumb_HT_VeryShort 8 TAB      &Thumb_HT_Normal 7 ESCAPE   &none                          &none                           &none        &Backspase_MacLike_mod_morph  &kp ENTER     &Thumb_HT_VeryShort 4 SPACE
            >;
        };

        Mac-UA {
            /*
                Keys physically like UA Colemak, but produce correct letters when system is QWERTY (UA).
                This allows to type on devices where Colemak is not supported.
                Use Cases:
                    - iPad
                    - other people's machines
                    - remote Mac / Machines where you don't bother yourself or not allowed to set Colemak
            */

            bindings = <
&kp Z                          &kp I                         &Layer_Tap_Timeless_Left 26 A  &P_Tabs_Timeless_left 0 G   &kp U                                    &kp Q                       &Layer_Tap_Timeless_Right 9 K  &Layer_Tap_Timeless_Right 26 E  &kp B                       &kp LEFT_SHIFT
&kp LEFT_SHIFT                 &Mac_GLOBE_nonEN_WA_LHRM 0 F  &Mac_CTRL_nonEN_WA_LHRM 0 H    &Mac_OPT_nonEN_WA_LHRM 0 C  &Mac_CMD_nonEN_WA_LHRM 0 N               &D_Tasks_Timeless_left 0 L  &kp X                          &Mac_CMD_nonEN_WA_RHRM 0 Y      &Mac_OPT_nonEN_WA_RHRM 0 T  &Mac_CTRL_nonEN_WA_RHRM 0 S  &Mac_GLOBE_nonEN_WA_RHRM 0 J
&Layer_Tap_Timeless_Left 12 P  &lt 21 KP_NUMBER_6            &lt 22 W                       &lt 20 D                    &Layer_Tap_Timeless_Left 11 KP_NUMBER_1  &kp R                       &kp V                          &Test_Mac_UA_Nonfits            &kp PERIOD                  &kp SLASH
                               &trans                        &trans                         &trans                      &trans                                   &trans                      &trans                         &trans                          &trans                      &trans                       &trans                        &Thumb_HT_VeryShort 4 SPACE
            >;
        };

        iPad-EN {
            bindings = <
&kp Q                          &kp W         &Layer_Tap_Timeless_Left 26 F  &P_Tabs_Timeless_left 0 P      &kp G                          &kp J                       &Layer_Tap_Timeless_Right 9 L  &Layer_Tap_Timeless_Right 26 U  &kp Y        &kp LEFT_SHIFT
&kp LEFT_SHIFT                 &hml GLOBE A  &hml LEFT_CONTROL R            &hml LALT S                    &hml LCMD T                    &D_Tasks_Timeless_left 0 D  &kp H                          &hmr LCMD N                     &hmr LALT E  &hmr LEFT_CONTROL I           &hmr GLOBE O
&Layer_Tap_Timeless_Left 12 Z  &lt 21 X      &lt 22 C                       &lt 20 V                       &Layer_Tap_Timeless_Left 11 B  &kp K                       &kp M                          &kp COMMA                       &kp DOT      &kp FSLH
                               &tog_on 7     &mo 28                         &HyperMac_HT_Timeless 0 SPACE  &Thumb_HT_VeryShort 8 TAB      &Thumb_HT_Normal 7 ESCAPE   &none                          &none                           &none        &Backspase_MacLike_mod_morph  &kp ENTER     &Thumb_HT_VeryShort 4 SPACE
            >;
        };

        iPad-UA {
            bindings = <
&kp Z                          &kp I                             &Layer_Tap_Timeless_Left 26 A    &P_Tabs_Timeless_left 0 G       &kp U                              &kp Q                       &Layer_Tap_Timeless_Right 9 K  &Layer_Tap_Timeless_Right 26 E  &kp B                           &kp LEFT_SHIFT
&kp LEFT_SHIFT                 &iPad_GLOBE_Phonetic_UA_LHRM 0 F  &iPad_CTRL_Phonetic_UA_LHRM 0 H  &iPad_OPT_Phonetic_UA_LHRM 0 C  &iPad_CMD_Phonetic_UA_LHRM 0 N     &D_Tasks_Timeless_left 0 L  &kp X                          &iPad_CMD_Phonetic_UA_RHRM 0 Y  &iPad_OPT_Phonetic_UA_RHRM 0 T  &iPad_CTRL_Phonetic_UA_RHRM 0 S  &iPad_GLOBE_Phonetic_UA_RHRM 0 J
&Layer_Tap_Timeless_Left 12 P  &lt 21 LEFT_BRACKET               &lt 22 W                         &lt 20 D                        &Layer_Tap_Timeless_Left 11 COMMA  &kp R                       &kp V                          &Test_iPad_UA_Nonfits           &kp SLASH                       &kp LC(LA(SLASH))
                               &trans                            &trans                           &trans                          &trans                             &trans                      &trans                         &trans                          &trans                          &trans                           &trans                            &Thumb_HT_VeryShort 5 SPACE
            >;
        };

        Mac-EN-UA-Symbols {
            /*
                &hml LEFT_COMMAND LEFT_PARENTHESIS
                    is to make CMD-+ shortcut (increase/decrease browrer page) layer- & key-race agnostic.
                    So it worked not only when you hit cmd-mo(symbol layer)-kp(+/-) but even
                    when you key-rased as mo(symbol layer)- kp(cmd)-kp(+/-). Try with hands and you understand
            */

            bindings = <
&kp EXCL        &kp UNDER  &kp LESS_THAN  &kp LEFT_BRACKET  &kp GRAVE                           &kp HASH                 &kp RIGHT_BRACKET  &kp GREATER_THAN                     &kp AMPERSAND    &trans
&kp LEFT_SHIFT  &kp EQUAL  &kp MINUS      &hml LALT PLUS    &hml LEFT_COMMAND LEFT_PARENTHESIS  &kp CARET                &kp DOLLAR         &hmr LEFT_COMMAND RIGHT_PARENTHESIS  &hmr LALT COLON  &kp DOUBLE_QUOTES  &kp APOSTROPHE
&kp BACKSLASH   &kp TILDE  &kp ASTERISK   &kp LEFT_BRACE    &kp PERCENT                         &kp AT                   &kp RIGHT_BRACE    &kp SEMI                             &kp PERIOD       &kp QUESTION
                &trans     &trans         &trans            &Symbols_System_Layouts_m           &Emoji_System_Layouts_m  &trans             &trans                               &trans           &trans             &trans          &trans
            >;
        };

        iPad-UA-Symbols {
            bindings = <
&kp EXCL               &kp UNDER  &kp LC(LA(LS(COMMA)))  &kp LC(LA(LEFT_BRACKET))      &kp LC(LA(GRAVE))                   &kp LA(N3)               &kp LC(LA(RIGHT_BRACKET))      &kp LA(LC(LG(PERIOD)))               &kp LA(LC(LS(N7)))             &trans
&kp LEFT_SHIFT         &kp EQUAL  &kp MINUS              &hml LALT PLUS                &hml LEFT_COMMAND LEFT_PARENTHESIS  &kp LA(N6)               &kp LA(N4)                     &hmr LEFT_COMMAND RIGHT_PARENTHESIS  &hmr (LEFT_ALT) LA(LC(COLON))  &kp LC(LA(LS(SINGLE_QUOTE)))  &kp LC(LA(APOSTROPHE))
&kp LA(LC(BACKSLASH))  &kp LA(M)  &kp LA(N8)             &kp LC(LA(LS(LEFT_BRACKET)))  &kp LS(N5)                          &kp LA(N2)               &kp LA(LC(LS(RIGHT_BRACKET)))  &kp LA(LC(SEMI))                     &kp LA(LC(PERIOD))             &kp LA(LS(LC(SLASH)))
                       &trans     &trans                 &trans                        &Symbols_System_Layouts_m           &Emoji_System_Layouts_m  &trans                         &trans                               &trans                         &trans                        &trans                  &trans
            >;
        };

        Symbols_and_Emoji_Sys_Layouts {
            bindings = <
&kp Q           &kp W                        &kp E                               &kp R                           &kp T                               &kp Y   &kp U   &kp I                               &kp O                           &kp LEFT_SHIFT
&kp LEFT_SHIFT  &ht_sys_sub_layouts GLOBE A  &ht_sys_sub_layouts LEFT_CONTROL S  &ht_sys_sub_layouts LEFT_ALT D  &ht_sys_sub_layouts LEFT_COMMAND F  &kp G   &kp H   &ht_sys_sub_layouts LEFT_COMMAND J  &ht_sys_sub_layouts LEFT_ALT K  &ht_sys_sub_layouts LEFT_CONTROL L  &ht_sys_sub_layouts GLOBE SEMICOLON
&kp Z           &kp X                        &kp C                               &kp V                           &kp B                               &kp N   &kp M   &kp COMMA                           &kp DOT                         &kp FSLH
                &trans                       &trans                              &trans                          &trans                              &trans  &trans  &trans                              &trans                          &trans                              &trans                               &trans
            >;
        };

        Numbers_And_Media {
            /*
                ← → Arrows - Youtube, VLC, some online players: skip Fast Forward/Backward/Rewind
                           Apple Music: duplicate function of Next/Previous track
                J/Shift    - Youtube: Faster Rewind (J)
                L          - Youtube: Fast Forward
                Shift      - compatibilyty for Scrensot Shortcuts & moving Tabs to N-th Desktop.
            */

            bindings = <
&kp LEFT_ARROW        &none             &none              &kp RIGHT_ARROW   &none       &kp KP_PLUS  &kp N7        &kp N8        &kp N9  &kp KP_MULTIPLY
&mt LEFT_SHIFT J      &kp C_PREVIOUS    &kp C_VOLUME_DOWN  &kp C_VOLUME_UP   &kp C_NEXT  &kp L        &kp KP_MINUS  &kp NUMBER_4  &kp N5  &kp N6           &kp KP_DIVIDE
&kp LS(LEFT_BRACKET)  &kp LEFT_BRACKET  &kp RIGHT_BRACKET  &kp C_PLAY_PAUSE  &kp C_MUTE  &kp KP_DOT   &kp N1        &kp N2        &kp N3  &kp NUMBER_0
                      &tog_of 7         &none              &trans            &trans      &none        &none         &none         &none   &trans           &trans         &Emoji_System_Layouts_m
            >;
        };

        NAV-Apple {
            display-name = "Nav-Apple";
            bindings = <
&none               &none   &none             &Tabs_Layer_m  &mo 10    &kp HOME          &kp PAGE_UP    &none     &none     &none
&trans              &trans  &kp LEFT_CONTROL  &kp LALT       &kp LCMD  &kp LEFT_CONTROL  &none          &kp LEFT  &kp DOWN  &kp UP_ARROW  &kp RIGHT
&kp LC(DOWN_ARROW)  &none   &none             &Flycut_m      &none     &kp END           &kp PAGE_DOWN  &none     &none     &none
                    &trans  &trans            &trans         &trans    &trans            &trans         &trans    &none     &trans        &trans     &Symbols_System_Layouts_m
            >;
        };

        NAV-Apple-TabsNav_rhsLayoutLhs {
            // F20 shortcuts here is an Amethyst layots selection. See more F20 in other layots

            bindings = <
&none  &none  &kp LC(F20)      &kp LA(LS(F20))  &none        &none            &Web_Page_Back_m  &none        &none    &Web_Page_Forward_m
&none  &none  &kp LS(LC(F20))  &none            &kp LG(F20)  &kp LG(LS(F20))  &none             &kp LS(TAB)  &kp TAB  &kp LS(TAB)          &kp TAB
&none  &none  &none            &none            &none        &none            &none             &none        &none    &none
       &none  &none            &none            &none        &none            &none             &none        &none    &none                &none    &none
            >;
        };

        NAV-Apple-BrowserGroupNav {
            bindings = <
&none  &none  &none  &none  &none  &none  &none  &none  &none                      &none
&none  &none  &none  &none  &none  &none  &none  &none  &kp LG(LA(RIGHT_BRACKET))  &kp LG(LA(LEFT_BRACKET))  &none
&none  &none  &none  &none  &none  &none  &none  &none  &none                      &none
       &none  &none  &none  &none  &none  &none  &none  &none                      &none                     &none  &none
            >;
        };

        NAV-Apple-WorkSpaceApps {
            bindings = <
&none  &none  &none  &none  &none  &none  &none  &none          &none  &none
&none  &none  &none  &none  &none  &none  &none  &kp LS(LA(J))  &none  &none  &kp LA(LS(K))
&none  &none  &none  &none  &none  &none  &none  &none          &none  &none
       &none  &none  &none  &none  &none  &none  &none          &none  &none  &none          &none
            >;
        };

        NAV-Apple-AppWindowsCycle {
            /*
                F20 shortcuts here is an Amethyst risizing in split view and so. See more F20 in other layots
                F11-xx - Switch between Idea/others Focus Editor (E-Editor) & last Tool Window (I-Instruments)
                App Window Switching:
                    - on Right: is regular way to switch. There only left and right arrows
                    - on Left: a) is onehanded switcing, I need when another hand ocupied with mouse. When left hand
                                  enters this layer with Z, it's motorics is limited and not its not pricise. Thus I
                                  made for left hand more keys to switch windows than two keys for the right hand.
                                  They are at positions A=R and S=T.
                               b) Plus, one handed swithing with layer is dublicated by AppWindowsSw.. combos.
                                  Because due to mentioned bad motirics, I often roll keys and have false poritives
                                  whet A/R/S/T resolved to taps. So I've edded combos wich envolve same keys Z+ARST
                                  wich handles earlier before false positive tap. In such way if I roll - combos cover
                                  me and make window swithch. And when I not roll - hold tap layer.
                     Check commits for denails: e29b7d37b4909a3cf55622e44247970dd6e427ba
                                                7906a3aa615c9d78b2ecc074df472e8c55564eea
                                                1f7d926b460bcf9e383ee0efb16c31db201d0cb5
            */

            bindings = <
&none  &none              &none              &none          &none          &none  &kp LS(LG(LC(F20)))  &none              &none        &none
&none  &kp LS(LG(GRAVE))  &kp LS(LG(GRAVE))  &kp LG(GRAVE)  &kp LG(GRAVE)  &none  &kp LG(LA(LS(F20)))  &kp LS(LG(GRAVE))  &kp LC(F11)  &kp LC(LS(F11))  &kp LG(GRAVE)
&none  &none              &none              &none          &none          &none  &kp LA(LS(M))        &none              &none        &none
       &none              &none              &none          &none          &none  &none                &none              &none        &none            &kp LA(LS(ENTER))  &none
            >;
        };

        NAV-Ubuntu {
            display-name = "NAV-Ubuntu";
            bindings = <
&none   &none   &none             &none             &mo 15  &kp HOME  &kp PAGE_UP    &none     &none     &none
&trans  &trans  &kp LEFT_CONTROL  &kp LEFT_CONTROL  &mo 23  &none     &none          &kp LEFT  &kp DOWN  &kp UP_ARROW  &kp RIGHT
&none   &none   &none             &none             &none   &kp END   &kp PAGE_DOWN  &none     &none     &none
        &trans  &trans            &trans            &trans  &trans    &trans         &trans    &none     &trans        &trans     &trans
            >;
        };

        NAV-Ubuntu-TabsNav {
            bindings = <
&none  &none  &none  &none  &none  &none  &kp LG(LEFT_BRACKET)  &none            &none  &kp LG(RIGHT_BRACKET)
&none  &none  &none  &none  &none  &none  &none                 &kp LC(LS(TAB))  &none  &none                  &kp LC(TAB)
&none  &none  &none  &none  &none  &none  &none                 &none            &none  &none
       &none  &none  &none  &none  &none  &none                 &none            &none  &none                  &none        &none
            >;
        };

        NAV-NotExist-Ubuntu-BrowGrupNav {
            // On ubuntu I Use only Chrome/Firefox, and both has no option to navigate between tab groups by keyboard

            display-name = "Not-Used. Read comments";
            bindings = <
&none  &none  &none  &none  &none  &none  &none  &none  &none                      &none
&none  &none  &none  &none  &none  &none  &none  &none  &kp LG(LA(RIGHT_BRACKET))  &kp LG(LA(LEFT_BRACKET))  &none
&none  &none  &none  &none  &none  &none  &none  &none  &none                      &none
       &none  &none  &none  &none  &none  &none  &none  &none                      &none                     &none  &none
            >;
        };

        NAV-Ubuntu-WorkSpaceAppCycle {
            bindings = <
&none  &none  &none  &none  &none  &none  &none  &none           &none  &none
&none  &none  &none  &none  &none  &none  &none  &kp LS(ESCAPE)  &none  &none  &kp ESC
&none  &none  &none  &none  &none  &none  &none  &none           &none  &none
       &none  &none  &none  &none  &none  &none  &none           &none  &none  &none    &none
            >;
        };

        NAV-Ubuntu-AppWindowsCycle {
            bindings = <
&none  &none  &none  &none  &none  &none  &none  &none       &none  &none
&none  &none  &none  &none  &none  &none  &none  &kp LS(F6)  &none  &none  &kp F6
&none  &none  &none  &none  &none  &none  &none  &none       &none  &none
       &none  &none  &none  &none  &none  &none  &none       &none  &none  &none   &none
            >;
        };

        Test-UA-Mac-non-fits {
            bindings = <
&none      &kp KP_NUMBER_8  &none   &none   &kp KP_NUMBER_2  &kp KP_NUMBER_0  &none   &kp KP_NUMBER_4  &none            &kp LSHFT
&kp LSHFT  &none            &none   &none   &none            &none            &none   &none            &kp KP_NUMBER_3  &kp KP_NUMBER_5  &none
&none      &none            &none   &none   &none            &kp KP_NUMBER_7  &none   &none            &none            &none
           &trans           &trans  &trans  &trans           &trans           &trans  &trans           &trans           &trans           &trans  &trans
            >;
        };

        mouse_layer {
            /*
                cs4:check:   shortcuts on mouse layer is "get info" on files and open containig dir in music app and are
                temporary amenity while im reviewing a ton of music
            */

            display-name = "mouse";
            bindings = <
&trans  &trans  &kp LS(LG(R))  &kp LG(I)  &none   &none   &none            &none           &none           &none
&trans  &trans  &kp LG(I)      &trans     &trans  &none   &none            &mmv MOVE_LEFT  &mmv MOVE_DOWN  &mmv MOVE_UP    &mmv MOVE_RIGHT
&none   &trans  &trans         &trans     &none   &none   &msc SCRL_RIGHT  &msc SCRL_UP    &msc SCRL_DOWN  &msc SCRL_LEFT
        &trans  &trans         &trans     &trans  &trans  &trans           &trans          &none           &trans          &mkp LCLK        &mkp RCLK
            >;
        };

        mouse_warp {
            bindings = <
&trans  &trans  &trans  &trans  &trans  &trans  &trans  &trans  &trans  &trans
&trans  &trans  &trans  &trans  &trans  &trans  &trans  &trans  &trans  &trans  &trans
&trans  &trans  &trans  &trans  &trans  &trans  &trans  &trans  &trans  &trans
        &trans  &trans  &trans  &trans  &trans  &trans  &trans  &trans  &trans  &trans  &trans
            >;
        };

        mouse_precision {
            bindings = <
&trans  &trans  &trans  &trans  &trans  &trans  &trans  &trans  &trans  &trans
&trans  &trans  &trans  &trans  &trans  &trans  &trans  &trans  &trans  &trans  &trans
&trans  &trans  &trans  &trans  &trans  &trans  &trans  &trans  &trans  &trans
        &trans  &trans  &trans  &trans  &trans  &trans  &trans  &trans  &trans  &trans  &trans
            >;
        };

        mouse_regular {
            bindings = <
&trans  &trans  &trans  &trans  &trans  &trans  &trans  &trans  &trans  &trans
&trans  &trans  &trans  &trans  &trans  &trans  &trans  &trans  &trans  &trans  &trans
&trans  &trans  &trans  &trans  &trans  &trans  &trans  &trans  &trans  &trans
        &trans  &trans  &trans  &trans  &trans  &trans  &trans  &trans  &trans  &trans  &trans
            >;
        };

        NAV-Ubuntu-line-st-end {
            bindings = <
&none  &none  &none  &none  &none  &none  &none  &none     &none  &none
&none  &none  &none  &none  &none  &none  &none  &kp HOME  &none  &none  &kp END
&none  &none  &none  &none  &none  &none  &none  &none     &none  &none
       &none  &none  &none  &none  &none  &none  &none     &none  &none  &none    &none
            >;
        };

        Colemak_Plain_and_Hyper {
            bindings = <
&kp Q           &kp W   &kp F   &kp P   &kp G   &kp J   &kp L   &kp U      &kp Y    &kp LEFT_SHIFT
&kp LEFT_SHIFT  &kp A   &kp R   &kp S   &kp T   &kp D   &kp H   &kp N      &kp E    &kp I           &kp O
&kp Z           &kp X   &kp C   &kp V   &kp B   &kp K   &kp M   &kp COMMA  &kp DOT  &kp FSLH
                &trans  &trans  &trans  &trans  &trans  &trans  &trans     &trans   &trans          &trans  &mo_Fx_w_unpress_its_Hypr_key_m
            >;
        };

        Fx {
            /*
                Set by "Conditional Alternative" technique.
                Usage:
                    Symbols Thumb key (asume its A) + Hyper Key (asume its B). Order agnostic.
                Implementation:
                    Fx Layer activation is order agnostic, i.e. it has two activation pathes: A-B keys, and B-H keys.
                    A-B:
                          "A" activates Symbols Layer, where "B" key activates Fx.
                    B-A
                        B is already designed to switch to Hyper Layer. But this switching does a bit more to
                        sustain Hyper flows work - it additinaly helds F16 pressed. Thus when A key is pressed as a
                        part of Fx switching route -it should not just &mo to Fx (as in A-B route) but depress F16.
                        For this &mo+depress the "A" key has macro. Another safety net which makes this route working,
                        is that F16 press, is never typed, because karabiner sallows it to set its "hyper" variable.
                Coupling:
                       - "A" & "B" keys
                       - Fx layer must be on top of the layers to which "A" & "B" keys switch
                       - macro that depresses F16 of hyper key.
                       - karabiner's Hyper. Which sallows F16 press to set its "hyper" variable, and never type it.
            */

            bindings = <
&none   &none              &none                &none        &none                &none            &kp F7           &kp F8  &kp F9  &kp F10
&trans  &hml LEFT_SHIFT A  &hml LEFT_CONTROL S  &hml LALT D  &hml LEFT_COMMAND F  &none            &kp KP_NUMBER_5  &kp F4  &kp F5  &kp F6   &kp F11
&none   &none              &none                &none        &none                &kp KP_NUMBER_5  &kp F1           &kp F2  &kp F3  &kp F12
        &trans             &trans               &trans       &trans               &trans           &trans           &trans  &trans  &trans   &trans   &trans
            >;
        };

        Apps {
            bindings = <
&App_Q_TD  &App_W_TD  &App_F_TD  &App_P_TD  &App_G_TD  &App_J_TD  &App_L_TD  &App_U_TD  &App_Y_TD  &none
&none      &App_A_TD  &App_R_TD  &App_S_TD  &App_T_TD  &App_D_TD  &App_H_TD  &App_N_TD  &App_E_TD  &App_I_TD  &App_O_TD
&App_Z_TD  &App_X_TD  &App_C_TD  &App_V_TD  &App_B_TD  &App_K_TD  &App_M_TD  &none      &none      &none
           &none      &none      &none      &none      &none      &none      &none      &none      &none      &none      &none
            >;
        };

        Ubuntu {
            bindings = <
&kp Q                        &kp W                &kp F                &Layer_Tap_Timeless_Left 14 P  &kp G                   &trans  &trans  &trans               &trans       &trans
&kp LEFT_SHIFT               &hml LEFT_COMMAND A  &hml LEFT_CONTROL R  &hml LALT S                    &hml LEFT_CONTROL T     &kp D   &none   &hmr LEFT_CONTROL N  &hmr LALT E  &hmr LEFT_CONTROL I  &hmr LEFT_COMMAND O
&UbuntuAppSwWA_Timeless 0 Z  &lt 21 X             &lt 22 C             &lt 20 V                       &UbuntuWindowsSwWA 0 B  &trans  &trans  &trans               &trans       &trans
                             &trans               &trans               &trans                         &lt 13 TAB              &trans  &trans  &trans               &trans       &trans               &trans               &trans
            >;
        };

        Adjust {
            display-name = "BT, workarounds";
            bindings = <
&tog 0    &tog 1      &tog 0      &iPhone_BT_m  &tog 5        &none         &trans     &Ubuntu_BT_m  &none    &tog 26
&kp CAPS  &none       &bt BT_PRV  &bt BT_NXT    &bt BT_SEL 2  &bt BT_SEL 3  &trans     &trans        &trans   &iPad_BT_m  &none
&trans    &trans      &none       &kp INSERT    &out OUT_BLE  &none         &Mac_BT_m  &trans        &none    &none
          &sys_reset  &none       &none         &none         &none         &none      &sys_reset    &kt F15  &bt BT_CLR  &none  &none
            >;
        };

        Test_iPad_non_fits {
            bindings = <
&none      &kp O   &none   &none   &kp GRAVE  &kp SEMI  &none   &kp PERIOD  &none           &kp LSHFT
&kp LSHFT  &none   &none   &none   &none      &none     &none   &none       &kp APOSTROPHE  &kp RIGHT_BRACKET  &none
&none      &none   &none   &none   &none      &kp M     &none   &none       &none           &none
           &trans  &trans  &trans  &trans     &trans    &trans  &trans      &trans          &trans             &trans  &trans
            >;
        };
    };

    conditional_layers {
        compatible = "zmk,conditional-layers";

        MouseWarpConditional {
            if-layers = <20>;
            then-layer = <19>;
        };

        MousePrecisionConditional {
            if-layers = <21>;
            then-layer = <19>;
        };

        MouseRegularConditional {
            if-layers = <22>;
            then-layer = <19>;
        };
    };
};
